# CC1314R10 register map
File version: 1.0
CPU: CM33 1.0, other endian, MPU, FPU, 3 interrupt priority bits
Registers are 32-bit, read-write, reset 0x0 unless marked. A register's access mark holds for its fields unless they carry their own. Offsets are from the block's base; [hi:lo] are bit positions.

## AON_PMCTL — This component control the Power Management controller residing in the AON domain. Note: This module is only supporting 32 bit Read Write access from MCU
Base 0x58090000
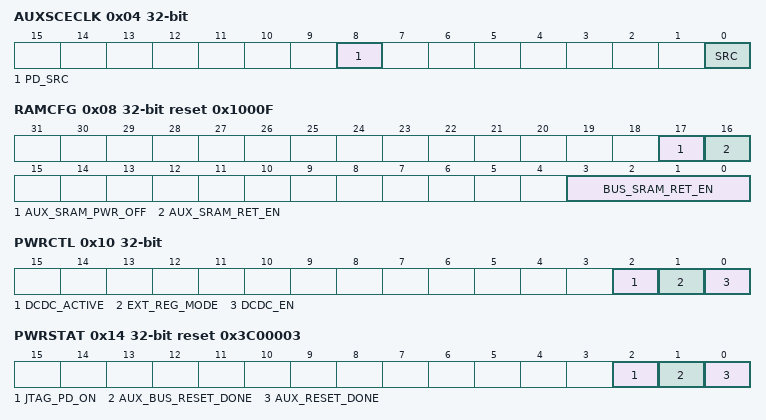
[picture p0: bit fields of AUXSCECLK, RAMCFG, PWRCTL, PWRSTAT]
0x04 AUXSCECLK — AUX SCE Clock Management This register contains bitfields that are relevant for setting up the clock to the AUX domain.
  [8] PD_SRC — [8:8] Selects the clock source for the AUX domain when AUX is in powerdown mode. Note: Switching the clock source is guaranteed to be glitch-free
    1=SCLK_LF (LF clock (SCLK_LF )); 0=NO_CLOCK
  [0] SRC — [0:0] Selects the clock source for the AUX domain when AUX is in active mode. Note: Switching the clock source is guaranteed to be glitch-free
    1=SCLK_MF (MF Clock (SCLK_MF)); 0=SCLK_HFDIV2 (HF Clock divided by 2 (SCLK_HFDIV2))
0x08 RAMCFG reset 0x1000F — RAM Configuration This register contains power management related configuration for the SRAM in the MCU and AUX domain.
  [17] AUX_SRAM_PWR_OFF — [17:17] Internal. Only to be used through TI provided API.
  [16] AUX_SRAM_RET_EN — [16:16] Internal. Only to be used through TI provided API.
  [3:0] BUS_SRAM_RET_EN — [3:0] MCU SRAM is partitioned into 8 banks . This register controls which of the banks that has retention during MCU Bus domain power off
    15=RET_FULL (Retention on for all banks BANK[0]: BANK[1]: BANK[2]: BANK[3]:BANK[4]: BANK[5]: BANK[6]: BANK[7] + PARITY_BANK retained); 7=RET_LEVEL3 (Retention on for BANK[0]: BANK[1]: BANK[2]: BANK[3]:BANK[4]: BANK[5] + PARITY_BANK retained); 3=RET_LEVEL2 (Retention on for BANK[0]: BANK[1]: BANK[2]: BANK[3]:BANK[4] + PARITY_BANK retained); 1=RET_LEVEL1 (Retention on for BANK[0]: BANK[1]: BANK[2]: BANK[3] + PARITY_BANK retained); 0=RET_NONE (Retention is disabled)
0x10 PWRCTL — Power Management Control This register controls bitfields for setting low level power management features such as selection of regulator for VDDR supply and control of IO ring where certain segments can be enabled / disabled.
  [2] DCDC_ACTIVE — [2:2] Select to use DCDC regulator for VDDR in active mode 0: Use GLDO for regulation of VDDR in active mode. 1: Use DCDC for regulation of VDDR in active mode. DCDC_EN must also be set for DCDC to be used as regulator for VDDR in active mode
  [1] EXT_REG_MODE ro — [1:1] Status of source for VDDRsupply: 0: DCDC or GLDO are generating VDDR 1: DCDC and GLDO are bypassed and an external regulator supplies VDDR
  [0] DCDC_EN — [0:0] Select to use DCDC regulator during recharge of VDDR 0: Use GLDO for recharge of VDDR 1: Use DCDC for recharge of VDDR Note: This bitfield should be set to the same as DCDC_ACTIVE
0x14 PWRSTAT reset 0x3C00003 — AON Power and Reset Status This register is used to monitor various power management related signals in AON. All other signals than JTAG_PD_ON, AUX_BUS_RESET_DONE, and AUX_RESET_DONE are for test, calibration and debug purpose only.
  [2] JTAG_PD_ON ro — [2:2] Indicates JTAG power state: 0: JTAG is powered off 1: JTAG is powered on
  [1] AUX_BUS_RESET_DONE ro — [1:1] Indicates Reset Done from AUX Bus: 0: AUX Bus is being reset 1: AUX Bus reset is released
  [0] AUX_RESET_DONE ro — [0:0] Indicates Reset Done from AUX: 0: AUX is being reset 1: AUX reset is released
0x18 SHUTDOWN — Shutdown Control This register contains bitfields required for entering shutdown mode
  [0] EN — [0:0] Shutdown control. 0: Do not write 0 to this bit. 1: Immediately start the process to enter shutdown mode
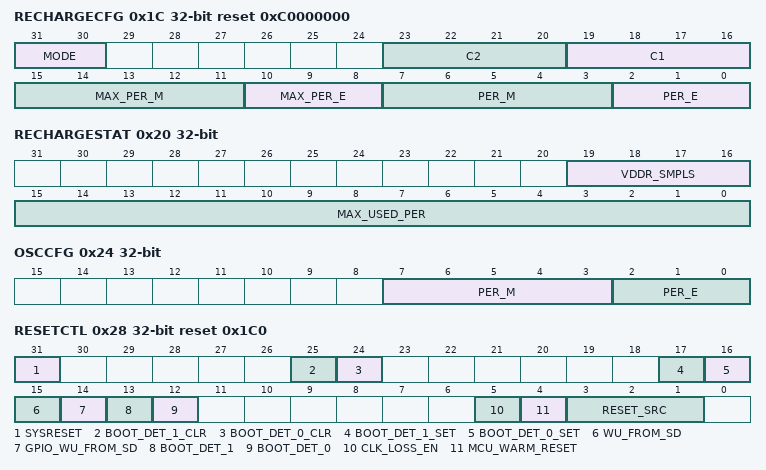
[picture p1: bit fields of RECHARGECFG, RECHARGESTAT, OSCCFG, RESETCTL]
0x1C RECHARGECFG reset 0xC0000000 — Recharge Controller Configuration This register sets all relevant parameters for controlling the recharge algorithm.
  [31:30] MODE — [31:30] Selects recharge algorithm for VDDR when the system is running on the uLDO
    3=COMPARATOR (External recharge comparator. Note that the clock to the recharge comparator must be enabled, [ANATOP_MMAP:ADI_3_REFSYS:CTL_RECHARGE_CMP0:COMP_CLK_DISABLE], before selecting this recharge algorithm.); 2=ADAPTIVE (Adaptive timer); 1=STATIC (Static timer); 0=OFF (Recharge disabled)
  [23:20] C2 — [23:20] Internal. Only to be used through TI provided API.
  [19:16] C1 — [19:16] Internal. Only to be used through TI provided API.
  [15:11] MAX_PER_M — [15:11] Internal. Only to be used through TI provided API.
  [10:8] MAX_PER_E — [10:8] Internal. Only to be used through TI provided API.
  [7:3] PER_M — [7:3] Internal. Only to be used through TI provided API.
  [2:0] PER_E — [2:0] Internal. Only to be used through TI provided API.
0x20 RECHARGESTAT — Recharge Controller Status This register controls various status registers which are updated during recharge. The register is mostly intended for test and debug.
  [19:16] VDDR_SMPLS ro — [19:16] The last 4 VDDR samples. For each bit: 0: VDDR was below VDDR_OK threshold when recharge started 1: VDDR was above VDDR_OK threshold when recharge started The register is updated prior to every recharge period with a shift left, and bit 0 is updated with the last VDDR sample.
  [15:0] MAX_USED_PER — [15:0] Shows the maximum number of 32kHz periods that have separated two recharge cycles and VDDR still was above VDDR_OK threshold when the latter recharge started. This register can be used as an indication of the leakage current during standby. This bitfield is cleared to 0 when writing this register.
0x24 OSCCFG — Oscillator Configuration This register sets the period for Amplitude compensation requests sent to the oscillator control system. The amplitude compensations is only applicable when XOSC_HF is running in low power mode.
  [7:3] PER_M — [7:3] Internal. Only to be used through TI provided API.
  [2:0] PER_E — [2:0] Internal. Only to be used through TI provided API.
0x28 RESETCTL reset 0x1C0 — Reset Management This register contains bitfields related to system reset such as reset source and reset request and control of brown out resets.
  [31] SYSRESET wo — [31:31] Cold reset register. Writing 1 to this bitfield will reset the entire chip and cause boot code to run again. 0: No effect 1: Generate system reset. Appears as SYSRESET in RESET_SRC
  [25] BOOT_DET_1_CLR wo — [25:25] Internal. Only to be used through TI provided API.
  [24] BOOT_DET_0_CLR wo — [24:24] Internal. Only to be used through TI provided API.
  [17] BOOT_DET_1_SET wo — [17:17] Internal. Only to be used through TI provided API.
  [16] BOOT_DET_0_SET wo — [16:16] Internal. Only to be used through TI provided API.
  [15] WU_FROM_SD ro — [15:15] A Wakeup from SHUTDOWN on an IO event has occurred, or a wakeup from SHUTDOWN has occurred as a result of the debugger being attached.. (TCK pin being forced low) Please refer to IOC:IOCFGn.WU_CFG for configuring the IO's as wakeup sources. 0: Wakeup occurred from cold reset or brown out as seen in RESET_SRC 1: A wakeup has occurred from SHUTDOWN Note: This flag will be cleared when SLEEPCTL.IO_PAD_SLEEP_DIS is asserted.
  [14] GPIO_WU_FROM_SD ro — [14:14] A wakeup from SHUTDOWN on an IO event has occurred Please refer to IOC:IOCFGn.WU_CFG for configuring the IO's as wakeup sources. 0: The wakeup did not occur from SHUTDOWN on an IO event 1: A wakeup from SHUTDOWN occurred from an IO event The case where WU_FROM_SD is asserted but this bitfield is not asserted will only occur in a debug session. The boot code will not proceed with wakeup from SHUTDOWN procedure until this bitfield is asserted as well. Note: This flag will be cleared when SLEEPCTL.IO_PAD_SLEEP_DIS is asserted.
  [13] BOOT_DET_1 ro — [13:13] Internal. Only to be used through TI provided API.
  [12] BOOT_DET_0 ro — [12:12] Internal. Only to be used through TI provided API.
  [5] CLK_LOSS_EN — [5:5] Controls reset generation in case SCLK_LF, SCLK_MF or SCLK_HF is lost when clock loss detection is enabled by [ANATOP_MMAP:DDI_0_OSC:CTL0.CLK_LOSS_EN] 0: Clock loss is ignored 1: Clock loss generates system reset Note: Clock loss reset generation must be disabled when changing clock source for SCLK_LF. Failure to do so may result in a spurious system reset. Clock loss reset generation is controlled by [ANATOP_MMAP:DDI_0_OSC:CTL0.CLK_LOSS_EN]
  [4] MCU_WARM_RESET — [4:4] Internal. Only to be used through TI provided API.
  [3:1] RESET_SRC ro — [3:1] Shows the root cause of the last system reset. More than the reported reset source can have been active during the last system reset but only the root cause is reported. The capture feature is not rearmed until all off the possible reset sources have been released and the result has been copied to AON_PMCTL. During the copy and rearm process it is one 2MHz period in which and eventual new system reset will be reported as Power on reset regardless of the root cause.
    7=WARMRESET (Software reset via PRCM warm reset request); 6=SYSRESET (Software reset via SYSRESET or hardware power management timeout detection. Note: The hardware power management timeout circuit is always enabled.); 5=CLK_LOSS (SCLK_LF, SCLK_MF or SCLK_HF clock loss detect); 4=VDDR_LOSS (Brown out detect on VDDR); 2=VDDS_LOSS (Brown out detect on VDDS); 1=PIN_RESET (Reset pin); 0=PWR_ON (Power on reset)
0x2C SLEEPCTL — Sleep Control This register is used to unfreeze the IO pad ring after waking up from SHUTDOWN
  [0] IO_PAD_SLEEP_DIS — [0:0] Controls the I/O pad sleep mode. The boot code will set this bitfield automatically unless waking up from a SHUTDOWN ( RESETCTL.WU_FROM_SD is set). 0: I/O pad sleep mode is enabled, meaning all outputs and pad configurations are latched. Inputs are transparent if pad is configured as input before IO_PAD_SLEEP_DIS is set to 1 1: I/O pad sleep mode is disabled Application software must reconfigure the state for all IO's before setting this bitfield upon waking up from a SHUTDOWN to avoid glitches on pins.
0x34 JTAGCFG reset 0x100 — JTAG Configuration This register contains control for configuration of the JTAG domain. This includes permissions for each TAP.
  [8] JTAG_PD_FORCE_ON — [8:8] Controls JTAG Power domain power state: 0: Controlled exclusively by debug subsystem. (JTAG Power domain will be powered off unless a debugger is attached) 1: JTAG Power Domain is forced on, independent of debug subsystem. Note: The reset value causes JTAG Power domain to be powered on by default. Software must clear this bit to turn off the JTAG Power domain
0x3C JTAGUSERCODE reset 0xB99A02F — JTAG USERCODE Boot code copies the JTAG USERCODE to this register from where it is forwarded to the debug subsystem.
  [31:0] USER_CODE — [31:0] 32-bit JTAG USERCODE register feeding main JTAG TAP Note: This field can be locked by LOCKCFG.LOCK
0xC4 WDTLOAD — Configuration Load Value register
  [31:0] LOAD — [31:0] This register is the 32-bit interval value used by the 32-bit counter. When this register is written, the value is immediately loaded and the counter is restarted to count down from the new value. If this register is loaded with 0x0000.0000, a reset is immediately generated. Read from this register will return the current value of the counter
0xC8 WDTTEST — Test Mode
  [0] STALLEN — [0:0] WDT Stall Enable 0: The WDT timer continues counting if the CPU is stopped with a debugger. 1: If the CPU is stopped with a debugger, the WDT stops counting. Once the CPU is restarted, the WDT resumes counting.
0xD0 WDTLOCK — Lock
  [31:0] LOCK — [31:0] WDT Lock: A write of the value 0x1ACC.E551 unlocks the watchdog registers for write access. A write of any other value reapplies the lock, preventing any register updates A read of this register returns the following values: 0x0000.0000: Unlocked 0x0000.0001: Locked
